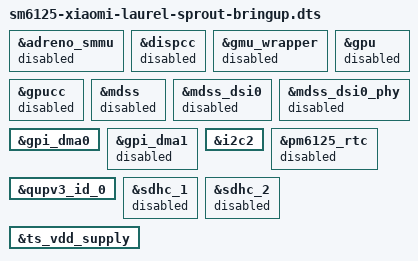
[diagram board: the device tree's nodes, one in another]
// SPDX-License-Identifier: BSD-3-Clause
/* First-boot profile: retain the bootloader framebuffer and core hardware. */

#include "sm6125-xiaomi-laurel-sprout.dts"

/* Native display/GPU takeover is enabled after a kernel log and ADB work. */
&adreno_smmu {
	status = "disabled";
};

&dispcc {
	status = "disabled";
};

&gmu_wrapper {
	status = "disabled";
};

&gpu {
	status = "disabled";
};

&gpucc {
	status = "disabled";
};

&mdss {
	status = "disabled";
};

&mdss_dsi0 {
	status = "disabled";
};

&mdss_dsi0_phy {
	status = "disabled";
};

/* FT3518 touch: enable only its QUP wrapper, I2C engine, DMA and supply. */
&gpi_dma0 {
	status = "okay";
};

&gpi_dma1 {
	status = "disabled";
};

&i2c2 {
	status = "okay";
};

&pm6125_rtc {
	status = "disabled";
};

&qupv3_id_0 {
	status = "okay";
};

&sdhc_1 {
	status = "disabled";
};

&sdhc_2 {
	status = "disabled";
};

&ts_vdd_supply {
	status = "okay";
};
